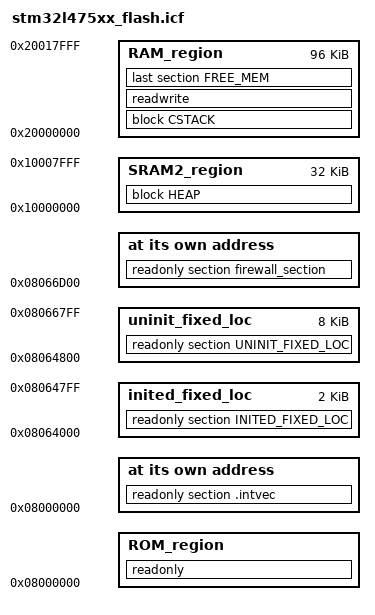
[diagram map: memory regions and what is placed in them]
/*###ICF### Section handled by ICF editor, don't touch! ****/
/*-Editor annotation file-*/
/* IcfEditorFile="$TOOLKIT_DIR$\config\ide\IcfEditor\cortex_v1_0.xml" */
/*-Specials-*/
define symbol __ICFEDIT_intvec_start__ = 0x08000000;
/*-Memory Regions-*/
define symbol __ICFEDIT_region_ROM_start__   = 0x08000000;
define symbol __ICFEDIT_region_ROM_end__     = 0x0807ffff;
define symbol __ICFEDIT_region_RAM_start__   = 0x20000000;
define symbol __ICFEDIT_region_RAM_end__     = 0x20017FFF;
define symbol __ICFEDIT_region_SRAM2_start__ = 0x10000000;
define symbol __ICFEDIT_region_SRAM2_end__   = 0x10007FFF;

/*-Sizes-*/
define symbol __ICFEDIT_size_cstack__ = 0x800;
define symbol __ICFEDIT_size_heap__   = 0x400;
/**** End of ICF editor section. ###ICF###*/

/* need more HEAP to run with mosquitto and RSA keys  0x7000 (exactly 0x6B6C )instead of 0x5800 with firewall ! */

define memory mem with size = 4G;

/* Definition of the static memory section for TLS certificates, keys, and wifi configuration data at the end of the first bank:
 *  Provision of 9K , 0x2400 bytes
 */
define symbol __ICFEDIT_region_FIXED_LOC_start__ = 0x08064000;
define region inited_fixed_loc = mem:[from __ICFEDIT_region_FIXED_LOC_start__ size 2K];
define region uninit_fixed_loc = mem:[from __ICFEDIT_region_FIXED_LOC_start__ + 2K size 8K];

define region ROM_region      = mem:[from __ICFEDIT_region_ROM_start__   to __ICFEDIT_region_ROM_end__] - uninit_fixed_loc;
define region RAM_region      = mem:[from __ICFEDIT_region_RAM_start__   to __ICFEDIT_region_RAM_end__] ;
define region SRAM2_region    = mem:[from __ICFEDIT_region_SRAM2_start__   to __ICFEDIT_region_SRAM2_end__];


define block CSTACK    with alignment = 8, size = __ICFEDIT_size_cstack__   { };
define block HEAP      with alignment = 8, size = __ICFEDIT_size_heap__     { };

initialize by copy { readwrite };
do not initialize  { section .noinit };

define exported symbol __firewall_ROM_start = 0x08066D00;
place at address mem:__firewall_ROM_start { readonly section firewall_section };


place at address mem:__ICFEDIT_intvec_start__ { readonly section .intvec };

place in ROM_region   { readonly };
place in RAM_region   { block CSTACK,
                        readwrite };
place in RAM_region    { last section FREE_MEM};
place in SRAM2_region { block HEAP };
						
place in uninit_fixed_loc  { readonly section UNINIT_FIXED_LOC };
place in inited_fixed_loc  { readonly section INITED_FIXED_LOC };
